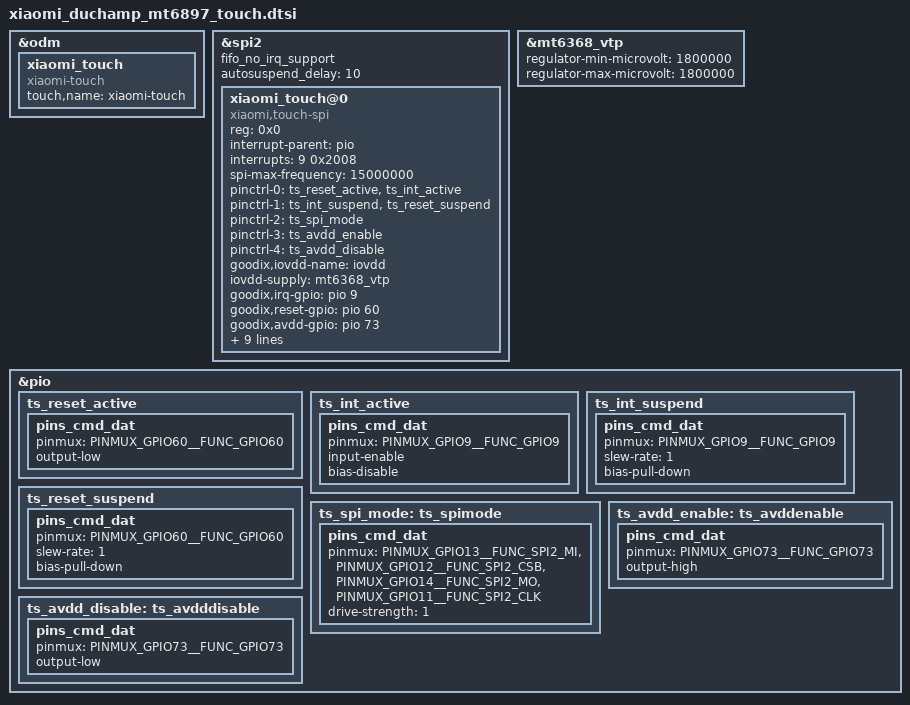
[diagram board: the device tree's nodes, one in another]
// SPDX-License-Identifier: (GPL-2.0 OR MIT)
/*
 * Copyright (C) 2020 MediaTek Inc.
 * Copyright (C) 2022-2023 XiaoMi, Inc.
 */

/* TOUCH start */
&odm {
	xiaomi_touch: xiaomi_touch {
		compatible = "xiaomi-touch";
		status = "ok";
		touch,name = "xiaomi-touch";
	};
};

&spi2 {
	status = "okay";
	fifo_no_irq_support;
	autosuspend_delay = <10>;
	#address-cells = <1>;
	#size-cells = <0>;
	xiaomi_touch@0 {
		status = "ok";
		compatible = "xiaomi,touch-spi";
		reg = <0x0>;
		interrupt-parent = <&pio>;
		interrupts = <9 0x2008>;
		spi-max-frequency = <15000000>;
		pinctrl-names = "pmx_ts_active", "pmx_ts_suspend", "pmx_gt_spi_mode", "pmx_ts_avdd_enable", "pmx_ts_avdd_disable";
		pinctrl-0 = <&ts_reset_active &ts_int_active>;
		pinctrl-1 = <&ts_int_suspend &ts_reset_suspend>;
		pinctrl-2 = <&ts_spi_mode>;
		pinctrl-3 = <&ts_avdd_enable>;
		pinctrl-4 = <&ts_avdd_disable>;

		/* gtp dtsi start */
		goodix,iovdd-name = "iovdd";
		iovdd-supply = <&mt6368_vtp>;
		goodix,irq-gpio = <&pio 9 0x2008>;
		goodix,reset-gpio = <&pio 60 0x00>;
		goodix,avdd-gpio = <&pio 73 0x00>;
		goodix,irq-flags = <2>;
		goodix,panel-max-x = <19520>;
		goodix,panel-max-y = <43392>;
		goodix,panel-max-w = <255>;
		goodix,panel-max-p = <4096>;
		goodix,firmware-name = "goodix_firmware_duchamp";
		goodix,config-name = "goodix_cfg_group_duchamp";
		goodix,touch-expert-array = <2 3 2 2
					     4 3 3 2
					     3 3 4 2>;
		/* gtp dtsi end */
	};
};

&mt6368_vtp {
	regulator-min-microvolt = <1800000>;
	regulator-max-microvolt = <1800000>;
};

&pio {
	ts_reset_active: ts_reset_active {
		pins_cmd_dat {
			pinmux = <PINMUX_GPIO60__FUNC_GPIO60>;
			output-low;
		};
	};
	ts_int_active: ts_int_active {
		pins_cmd_dat {
			pinmux = <PINMUX_GPIO9__FUNC_GPIO9>;
			input-enable;
			bias-disable;
		};
	};
	ts_int_suspend: ts_int_suspend {
		pins_cmd_dat {
			pinmux = <PINMUX_GPIO9__FUNC_GPIO9>;
			slew-rate = <1>;
			bias-pull-down;
		};
	};
	ts_reset_suspend: ts_reset_suspend {
		pins_cmd_dat {
			pinmux = <PINMUX_GPIO60__FUNC_GPIO60>;
			slew-rate = <1>;
			bias-pull-down;
		};
	};
	ts_spi_mode: ts_spimode {
		pins_cmd_dat {
			pinmux = <PINMUX_GPIO13__FUNC_SPI2_MI>,
				<PINMUX_GPIO12__FUNC_SPI2_CSB>,
				<PINMUX_GPIO14__FUNC_SPI2_MO>,
				<PINMUX_GPIO11__FUNC_SPI2_CLK>;
			drive-strength = <1>;
		};
	};
	ts_avdd_enable: ts_avddenable {
		pins_cmd_dat {
			pinmux = <PINMUX_GPIO73__FUNC_GPIO73>;
			output-high;
		};
	};
	ts_avdd_disable: ts_avdddisable {
		pins_cmd_dat {
			pinmux = <PINMUX_GPIO73__FUNC_GPIO73>;
			output-low;
		};
	};
};
/* TOUCH end */

